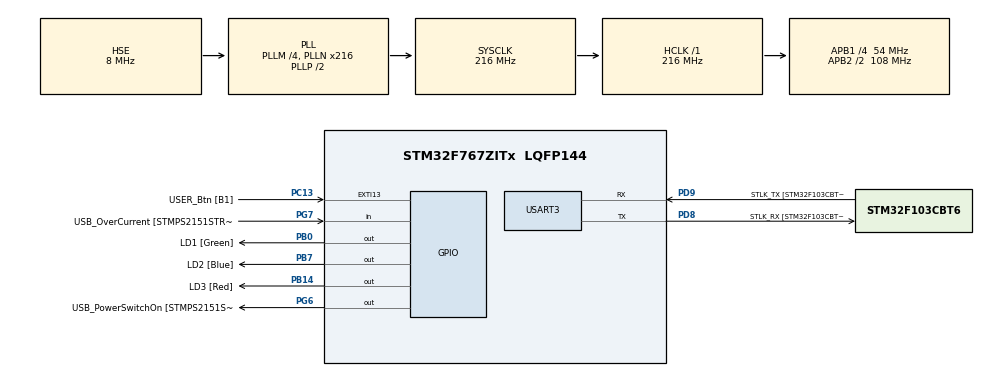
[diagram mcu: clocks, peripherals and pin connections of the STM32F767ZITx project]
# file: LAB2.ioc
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Mcu.Family=STM32F7
RCC.CortexFreq_Value=216000000
FREERTOS.BinarySemaphores01=myBinarySem01,Dynamic,NULL
PG6.Signal=GPIO_Output
PB14.GPIO_Label=LD3 [Red]
PG6.GPIO_Label=USB_PowerSwitchOn [STMPS2151STR_EN]
PA14.GPIO_Label=TCK
RCC.SYSCLKSourceVirtual=RCC_SYSCLKSOURCE_PLLCLK
PB0.GPIO_Label=LD1 [Green]
PC14/OSC32_IN.Mode=LSE-External-Oscillator
PC13.GPIO_Label=USER_Btn [B1]
PB13.GPIO_Label=RMII_TXD1 [LAN8742A-CZ-TR_TXD1]
PB13.Signal=ETH_TXD1
PG13.Signal=ETH_TXD0
PD9.Mode=Asynchronous
PG11.Signal=ETH_TX_EN
RCC.SYSCLKSource=RCC_SYSCLKSOURCE_PLLCLK
ProjectManager.StackSize=0x400
VP_FREERTOS_VS_CMSIS_V2.Mode=CMSIS_V2
USART3.VirtualMode-Asynchronous=VM_ASYNC
PA12.Signal=USB_OTG_FS_DP
PH0/OSC_IN.Mode=HSE-External-Clock-Source
RCC.HCLKFreq_Value=216000000
RCC.APB2TimFreq_Value=216000000
PH1/OSC_OUT.Signal=RCC_OSC_OUT
PD8.Signal=USART3_TX
RCC.AHBFreq_Value=216000000
NVIC.EXTI15_10_IRQn=true\:5\:0\:false\:false\:true\:true\:true\:true
RCC.HSE_VALUE=8000000
NVIC.TIM8_TRG_COM_TIM14_IRQn=true\:0\:0\:false\:false\:true\:false\:false\:true
RCC.PLLMUL=RCC_PLL_MUL9
PC4.GPIO_Label=RMII_RXD0 [LAN8742A-CZ-TR_RXD0]
PA14.Mode=Serial_Wire
PA10.GPIO_Label=USB_ID
PB7.Signal=GPIO_Output
PA8.Signal=USB_OTG_FS_SOF
VP_SYS_VS_tim14.Mode=TIM14
PH1/OSC_OUT.Mode=HSE-External-Clock-Source
PB7.GPIO_Label=LD2 [Blue]
Mcu.Package=LQFP144
NVIC.TimeBase=TIM8_TRG_COM_TIM14_IRQn
PC14/OSC32_IN.Signal=RCC_OSC32_IN
PA2.GPIO_Label=RMII_MDIO [LAN8742A-CZ-TR_MDIO]
NVIC.TimeBaseIP=TIM14
PA10.Signal=USB_OTG_FS_ID
RCC.APB2CLKDivider=RCC_HCLK_DIV2
RCC.APB1TimFreq_Value=108000000
PG11.GPIO_Label=RMII_TX_EN [LAN8742A-CZ-TR_TXEN]
PC5.Signal=ETH_RXD1
PB3.GPIO_Label=SWO
RCC.PLLSourceVirtual=RCC_PLLSOURCE_HSE
FREERTOS.Tasks01=defaultTask,24,128,StartDefaultTask,Default,NULL,Dynamic,NULL,NULL
PG7.Signal=GPIO_Input
PD9.GPIO_Label=STLK_TX [STM32F103CBT6_PA2]
PC13.Signal=GPXTI13
PA9.GPIO_Label=USB_VBUS
PC4.Signal=ETH_RXD0
PA11.GPIO_Label=USB_DM
PD9.Signal=USART3_RX
RCC.APB1CLKDivider=RCC_HCLK_DIV4
PG13.GPIO_Label=RMII_TXD0 [LAN8742A-CZ-TR_TXD0]
PA12.GPIO_Label=USB_DP
PD8.GPIO_Label=STLK_RX [STM32F103CBT6_PA3]
PA13.Signal=SYS_JTMS-SWDIO
PA8.GPIO_Label=USB_SOF [TP1]
ProjectManager.TargetToolchain=STM32CubeIDE
PA9.Signal=USB_OTG_FS_VBUS
RCC.USBFreq_Value=48000000
PD8.Mode=Asynchronous
PA1.Signal=ETH_REF_CLK
PB14.Signal=GPIO_Output
board=NUCLEO-F767ZI
RCC.VCOOutputFreq_Value=432000000
PH0/OSC_IN.Signal=RCC_OSC_IN
RCC.APB2Freq_Value=108000000
RCC.PRESCALERUSB=RCC_USBCLKSOURCE_PLL_DIV1_5
PG7.GPIO_Label=USB_OverCurrent [STMPS2151STR_FAULT]
PA1.GPIO_Label=RMII_REF_CLK [LAN8742A-CZ-TR_REFCLK0]
PC1.GPIO_Label=RMII_MDC [LAN8742A-CZ-TR_MDC]
PA13.Mode=Serial_Wire
Mcu.Name=STM32F767ZITx
PA2.Signal=ETH_MDIO
PA13.GPIO_Label=TMS
RCC.48MHZClocksFreq_Value=24000000
PB3.Signal=SYS_JTDO-SWO
RCC.SYSCLKFreq_VALUE=216000000
PA7.GPIO_Label=RMII_CRS_DV [LAN8742A-CZ-TR_CRS_DV]
PC5.GPIO_Label=RMII_RXD1 [LAN8742A-CZ-TR_RXD1]
PC15/OSC32_OUT.Mode=LSE-External-Oscillator
PA11.Signal=USB_OTG_FS_DM
PA14.Signal=SYS_JTCK-SWCLK
ProjectManager.HeapSize=0x200
RCC.HSI_VALUE=16000000
PH0/OSC_IN.GPIO_Label=MCO [STM32F103CBT6_PA8]
RCC.PLLQ=9
NVIC.PriorityGroup=NVIC_PRIORITYGROUP_4
RCC.PLLM=4
RCC.PLLN=216
PC15/OSC32_OUT.Signal=RCC_OSC32_OUT
RCC.APB1Freq_Value=54000000
PB0.Signal=GPIO_Output
PC1.Signal=ETH_MDC
PA7.Signal=ETH_CRS_DV

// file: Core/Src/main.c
/* USER CODE BEGIN Header */
/**
  ******************************************************************************
  * @file           : main.c
  * @brief          : Main program body
  ******************************************************************************
  * @attention
  *
  * <h2><center>&copy; Copyright (c) 2021 STMicroelectronics.
  * All rights reserved.</center></h2>
  *
  * This software component is licensed by ST under BSD 3-Clause license,
  * the "License"; You may not use this file except in compliance with the
  * License. You may obtain a copy of the License at:
  *                        opensource.org/licenses/BSD-3-Clause
  *
  ******************************************************************************
  */
/* USER CODE END Header */
#include "main.h"
#include "cmsis_os.h"
#include "usart.h"
#include "gpio.h"

void SystemClock_Config(void);
void MX_FREERTOS_Init(void);

int main(void)
{

  /* MCU Configuration--------------------------------------------------------*/

  /* Reset of all peripherals, Initializes the Flash interface and the Systick. */
  HAL_Init();

  /* Configure the system clock */
  SystemClock_Config();

  /* Initialize all configured peripherals */
  MX_GPIO_Init();
  MX_USART3_UART_Init();

  /* Init scheduler */
  osKernelInitialize();  /* Call init function for freertos objects (in freertos.c) */
  MX_FREERTOS_Init();
  /* Start scheduler */
  osKernelStart();

  /* We should never get here as control is now taken by the scheduler */
  /* Infinite loop */
  while (1)
  {

  }
}

void SystemClock_Config(void)
{
  RCC_OscInitTypeDef RCC_OscInitStruct = {0};
  RCC_ClkInitTypeDef RCC_ClkInitStruct = {0};
  RCC_PeriphCLKInitTypeDef PeriphClkInitStruct = {0};

  /** Configure LSE Drive Capability
  */
  HAL_PWR_EnableBkUpAccess();
  /** Configure the main internal regulator output voltage
  */
  __HAL_RCC_PWR_CLK_ENABLE();
  __HAL_PWR_VOLTAGESCALING_CONFIG(PWR_REGULATOR_VOLTAGE_SCALE1);
  /** Initializes the RCC Oscillators according to the specified parameters
  * in the RCC_OscInitTypeDef structure.
  */
  RCC_OscInitStruct.OscillatorType = RCC_OSCILLATORTYPE_HSE;
  RCC_OscInitStruct.HSEState = RCC_HSE_BYPASS;
  RCC_OscInitStruct.PLL.PLLState = RCC_PLL_ON;
  RCC_OscInitStruct.PLL.PLLSource = RCC_PLLSOURCE_HSE;
  RCC_OscInitStruct.PLL.PLLM = 4;
  RCC_OscInitStruct.PLL.PLLN = 216;
  RCC_OscInitStruct.PLL.PLLP = RCC_PLLP_DIV2;
  RCC_OscInitStruct.PLL.PLLQ = 9;
  if (HAL_RCC_OscConfig(&RCC_OscInitStruct) != HAL_OK)
  {
    Error_Handler();
  }
  /** Activate the Over-Drive mode
  */
  if (HAL_PWREx_EnableOverDrive() != HAL_OK)
  {
    Error_Handler();
  }
  /** Initializes the CPU, AHB and APB buses clocks
  */
  RCC_ClkInitStruct.ClockType = RCC_CLOCKTYPE_HCLK|RCC_CLOCKTYPE_SYSCLK
                              |RCC_CLOCKTYPE_PCLK1|RCC_CLOCKTYPE_PCLK2;
  RCC_ClkInitStruct.SYSCLKSource = RCC_SYSCLKSOURCE_PLLCLK;
  RCC_ClkInitStruct.AHBCLKDivider = RCC_SYSCLK_DIV1;
  RCC_ClkInitStruct.APB1CLKDivider = RCC_HCLK_DIV4;
  RCC_ClkInitStruct.APB2CLKDivider = RCC_HCLK_DIV2;

  if (HAL_RCC_ClockConfig(&RCC_ClkInitStruct, FLASH_LATENCY_7) != HAL_OK)
  {
    Error_Handler();
  }
  PeriphClkInitStruct.PeriphClockSelection = RCC_PERIPHCLK_USART3;
  PeriphClkInitStruct.Usart3ClockSelection = RCC_USART3CLKSOURCE_PCLK1;
  if (HAL_RCCEx_PeriphCLKConfig(&PeriphClkInitStruct) != HAL_OK)
  {
    Error_Handler();
  }
}

 /**
  * @brief  Period elapsed callback in non blocking mode
  * @note   This function is called  when TIM14 interrupt took place, inside
  * HAL_TIM_IRQHandler(). It makes a direct call to HAL_IncTick() to increment
  * a global variable "uwTick" used as application time base.
  * @param  htim : TIM handle
  * @retval None
  */
void HAL_TIM_PeriodElapsedCallback(TIM_HandleTypeDef *htim)
{
  if (htim->Instance == TIM14) {
    HAL_IncTick();
  }
}

void Error_Handler(void)
{
  __disable_irq();
  while (1)
  {
  }
}

/************************ (C) COPYRIGHT STMicroelectronics *****END OF FILE****/

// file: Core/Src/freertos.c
/* USER CODE BEGIN Header */
/**
  ******************************************************************************
  * File Name          : freertos.c
  * Description        : Code for freertos applications
  ******************************************************************************
  * @attention
  *
  * <h2><center>&copy; Copyright (c) 2021 STMicroelectronics.
  * All rights reserved.</center></h2>
  *
  * This software component is licensed by ST under Ultimate Liberty license
  * SLA0044, the "License"; You may not use this file except in compliance with
  * the License. You may obtain a copy of the License at:
  *                             www.st.com/SLA0044
  *
  ******************************************************************************
  */
/* USER CODE END Header */

#include "FreeRTOS.h"
#include "task.h"
#include "main.h"
#include "cmsis_os.h"

/* Definitions for defaultTask */
osThreadId_t defaultTaskHandle;
const osThreadAttr_t defaultTask_attributes = {
  .name = "defaultTask",
  .stack_size = 128 * 4,
  .priority = (osPriority_t) osPriorityNormal,
};
/* Definitions for myBinarySem01 */
osSemaphoreId_t myBinarySem01Handle;
const osSemaphoreAttr_t myBinarySem01_attributes = {
  .name = "myBinarySem01"
};

void StartDefaultTask(void *argument);

void MX_FREERTOS_Init(void); /* (MISRA C 2004 rule 8.1) */

void MX_FREERTOS_Init(void) {

  /* Create the semaphores(s) */
  /* creation of myBinarySem01 */
  myBinarySem01Handle = osSemaphoreNew(1, 1, &myBinarySem01_attributes);

  /* Create the thread(s) */
  /* creation of defaultTask */
  defaultTaskHandle = osThreadNew(StartDefaultTask, NULL, &defaultTask_attributes);

}

void StartDefaultTask(void *argument)
{
  /* USER CODE BEGIN StartDefaultTask */

  /* Infinite loop */
  for(;;)
  {
	  osSemaphoreAcquire(myBinarySem01Handle, osWaitForever);

	  HAL_GPIO_TogglePin(LD1_GPIO_Port, LD1_Pin);
	  osDelay(1);
  }
  /* USER CODE END StartDefaultTask */
}

/* USER CODE BEGIN Application */
void HAL_GPIO_EXTI_Callback(uint16_t GPIO_Pin)
{
	static uint32_t temp;
    if (GPIO_Pin == USER_Btn_Pin) {

    	if((HAL_GetTick() - temp) > 200)
        	osSemaphoreRelease(myBinarySem01Handle);
    }
    while(HAL_GPIO_ReadPin(USER_Btn_GPIO_Port, USER_Btn_Pin) == RESET);
    temp = HAL_GetTick();
}

/* USER CODE END Application */

/************************ (C) COPYRIGHT STMicroelectronics *****END OF FILE****/
